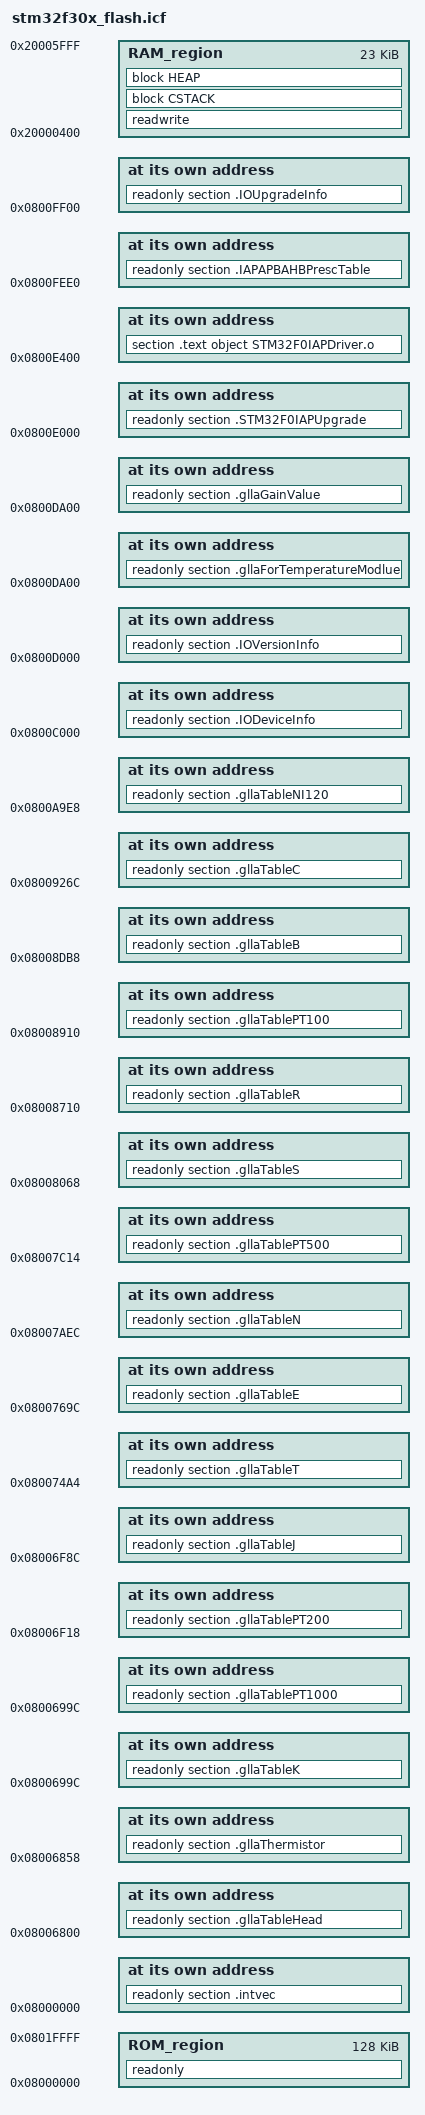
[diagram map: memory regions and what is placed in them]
/*###ICF### Section handled by ICF editor, don't touch! ****/
/*-Editor annotation file-*/
/* IcfEditorFile="$TOOLKIT_DIR$\config\ide\IcfEditor\cortex_v1_0.xml" */
/*-Specials-*/
define symbol __ICFEDIT_intvec_start__ = 0x08000000;
/*-Memory Regions-*/
define symbol __ICFEDIT_region_ROM_start__ = 0x08000000;
define symbol __ICFEDIT_region_ROM_end__   = 0x0801FFFF;

define symbol __ICFEDIT_region_RAM_start__ = 0x20000400;
define symbol __ICFEDIT_region_RAM_end__   = 0x20005FFF;

/*-Sizes-*/
define symbol __ICFEDIT_size_cstack__ = 0x400;
define symbol __ICFEDIT_size_heap__   = 0x200;
/**** End of ICF editor section. ###ICF###*/

define memory mem with size = 4G;
define region ROM_region   = mem:[from __ICFEDIT_region_ROM_start__   to __ICFEDIT_region_ROM_end__];
define region RAM_region   = mem:[from __ICFEDIT_region_RAM_start__   to __ICFEDIT_region_RAM_end__];
define block CSTACK    with alignment = 8, size = __ICFEDIT_size_cstack__   { };
define block HEAP      with alignment = 8, size = __ICFEDIT_size_heap__     { };

initialize by copy { readwrite };
do not initialize  { section .noinit };

place at address mem:__ICFEDIT_intvec_start__ { readonly section .intvec };
place at address mem:0x08006800 { readonly section .gllaTableHead };    
place at address mem:0x08006858 { readonly section .gllaThermistor };   
place at address mem:0x0800699c { readonly section .gllaTableK };
place at address mem:0x08006f8c { readonly section .gllaTableJ };
place at address mem:0x080074a4 { readonly section .gllaTableT };
place at address mem:0x0800769c { readonly section .gllaTableE };
place at address mem:0x08007aec { readonly section .gllaTableN };
place at address mem:0x08008068 { readonly section .gllaTableS };
place at address mem:0x08008710 { readonly section .gllaTableR };
place at address mem:0x08008db8 { readonly section .gllaTableB };
place at address mem:0x0800926c { readonly section .gllaTableC };

place at address mem:0x0800DA00 { readonly section .gllaForTemperatureModlue };

place at address mem:0x0800699c { readonly section .gllaTablePT1000 };
place at address mem:0x08006f18 { readonly section .gllaTablePT200 };
place at address mem:0x08007C14 { readonly section .gllaTablePT500 };
place at address mem:0x08008910 { readonly section .gllaTablePT100 };
place at address mem:0x0800A9E8 { readonly section .gllaTableNI120 };

place at address mem:0x0800C000 { readonly section .IODeviceInfo };
place at address mem:0x0800D000 { readonly section .IOVersionInfo };
place at address mem:0x0800DA00 { readonly section .gllaGainValue };
place at address mem:0x0800E000 { readonly section .STM32F0IAPUpgrade};
place at address mem:0x0800E400 { section .text object STM32F0IAPDriver.o };
place at address mem:0x0800FEE0 { readonly section .IAPAPBAHBPrescTable };
place at address mem:0x0800FF00 { readonly section .IOUpgradeInfo };



place in ROM_region   { readonly };
place in RAM_region   { readwrite,
                        block CSTACK, block HEAP };

export symbol __ICFEDIT_region_RAM_start__;
export symbol __ICFEDIT_region_RAM_end__;
